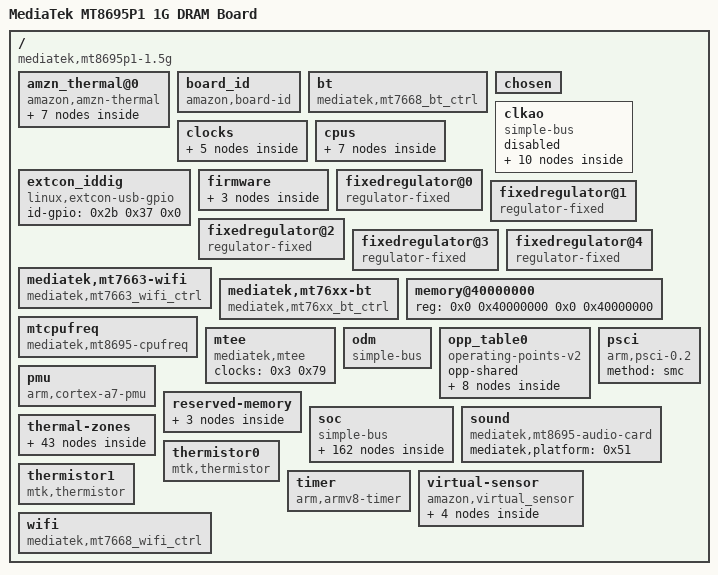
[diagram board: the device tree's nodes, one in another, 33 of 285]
/dts-v1/;

/ {
	#address-cells = <0x2>;
	#size-cells = <0x2>;
	compatible = "mediatek,mt8695p1-1.5g", "mediatek,mt8695";
	interrupt-parent = <0x1>;
	model = "MediaTek MT8695P1 1G DRAM Board";

	amzn_thermal@0 {
		compatible = "amazon,amzn-thermal";

		cooling_devices {

			cpucore_cool_cluster0 {
				cluster_id = <0x0>;
				device_type = "cpucore";
				dyn_coeff = <0x0>;
				min_state = <0x1>;
				node_name = "cpu_core_cluster0";
			};

			cpufreq_cool_cluster0 {
				cluster_id = <0x0>;
				device_type = "cpufreq";
				dyn_coeff = <0x8c>;
				min_state = <0xf4240>;
				node_name = "cpus";
			};

			gpufreq_cool {
				cluster_id = <0x0>;
				device_type = "gpufreq";
				dyn_coeff = <0x1b5>;
				min_state = <0x190>;
				node_name = "gpu";
			};

			wifi_cool_device {
				device_type = "wifi";
				min_state = <0x0>;
				node_name = "wifi_cool";
			};
		};

		cpu_core_cluster0 {
			#cooling-cells = <0x2>;
			linux,phandle = <0x49>;
			phandle = <0x49>;
		};

		wifi_cool {
			#cooling-cells = <0x2>;
			linux,phandle = <0x4b>;
			phandle = <0x4b>;
		};
	};

	board_id {
		compatible = "amazon,board-id";
		id0-gpio = <0x2b 0x4e 0x0>;
		id1-gpio = <0x2b 0x4f 0x0>;
		id2-gpio = <0x2b 0x50 0x0>;
	};

	bt {
		compatible = "mediatek,mt7668_bt_ctrl";
		interrupt-parent = <0x2b>;
		interrupts = <0x22 0x8>;
		pinctrl-0 = <0x40>;
		pinctrl-names = "default";
		status = "okay";
	};

	chosen {
		bootargs = "console=tty0 console=ttyS1,921600n1 earlycon=uart8250,mmio32,0x11003000 root=/dev/ram initrd=0x44000000,0x600000 loglevel=8 initcall_debug=1 androidboot.selinux=permissive androidboot.hardware=mt8695 androidboot.serialno=0123456789ABCDEF";
	};

	clkao {
		compatible = "simple-bus";
		status = "disabled";

		bring-up {
			clock-names = "0", "1", "2", "3", "4", "5", "6", "7", "8", "9", "10", "11", "12", "13", "14", "15", "16", "17", "18", "19", "20", "21", "22", "23", "24", "25", "26", "27", "28", "29", "30", "31", "32", "33", "34", "35", "36", "37", "38", "39", "40", "41", "42", "43", "44", "45", "46", "47", "48", "49", "50", "51", "52", "53", "54", "55", "56", "57", "58", "59", "60", "61", "62", "63", "64", "65", "66", "67", "68", "69", "70", "71", "72", "73", "74", "75", "76", "77", "78", "79", "80", "81", "82", "83", "84", "85", "86", "87", "88", "89", "90", "91", "92", "93", "94", "95", "96", "97", "98", "99", "100", "101", "102", "103", "104", "105", "106", "107", "108", "109", "110", "111", "112", "113", "114", "115", "116", "117", "118", "119", "120", "121", "122", "123", "124", "125", "126", "127", "128", "129", "130", "131", "132", "133", "134", "135", "136", "137", "138", "139", "140", "141", "142", "143", "144", "145", "146";
			clocks = <0x4 0x0 0x4 0x1 0x4 0x2 0x4 0x3 0x4 0x4 0x4 0x5 0x4 0x6 0x4 0x7 0x4 0x8 0x4 0x9 0x4 0xa 0x3 0x47 0x3 0x49 0x3 0x50 0x3 0x57 0x3 0x59 0x3 0x5d 0x3 0x5f 0x3 0x63 0x3 0x65 0x3 0x66 0x3 0x67 0x3 0x68 0x3 0x69 0x3 0x6a 0x3 0x6b 0x3 0x6c 0x3 0x6d 0x3 0x6e 0x3 0x6f 0x3 0x74 0x3 0x75 0x3 0x79 0x3 0x7a 0x3 0x7f 0x3 0x80 0x3 0x81 0x3 0x82 0x3 0x83 0x3 0x84 0x3 0x85 0x3 0x86 0x3 0x87 0x3 0x88 0xa 0x0 0xa 0x1 0xa 0x2 0xa 0x3 0xa 0x4 0x18 0x3 0x18 0x4 0x18 0x5 0x18 0x6 0x18 0x7 0x18 0x8 0x18 0x9 0x18 0xa 0x18 0xb 0x18 0xc 0x18 0xd 0x18 0xe 0x18 0xf 0x18 0x10 0x18 0x11 0x18 0x12 0x18 0x13 0x18 0x14 0x18 0x15 0x18 0x16 0x18 0x17 0x18 0x18 0x18 0x19 0x18 0x1a 0x18 0x1b 0x18 0x1c 0x18 0x1d 0x18 0x1e 0x18 0x1f 0x18 0x20 0x18 0x21 0x18 0x22 0x18 0x23 0x18 0x24 0x18 0x25 0x18 0x26 0x18 0x27 0x41 0x0 0x41 0x1 0x41 0x2 0x41 0x3 0x37 0x0 0x37 0x1 0x37 0x2 0x37 0x3 0x37 0x4 0x37 0x5 0x37 0x6 0x37 0x7 0x37 0x8 0x37 0x9 0x37 0xa 0x37 0xb 0x37 0xc 0x37 0xd 0x37 0xe 0x37 0xf 0x37 0x10 0x37 0x11 0x37 0x12 0x37 0x13 0x37 0x14 0x37 0x15 0x37 0x16 0x37 0x17 0x37 0x18 0x37 0x19 0x37 0x1a 0x37 0x1b 0x37 0x1c 0x37 0x1d 0x37 0x1e 0x38 0x0 0x38 0x1 0x38 0x2 0x38 0x3 0x38 0x4 0x38 0x5 0x38 0x6 0x38 0x7 0x38 0x8 0x38 0x9 0x38 0xa 0x38 0xb 0x38 0xc 0x38 0xd 0x38 0xe 0x38 0xf 0x38 0x10 0x3d 0x0 0x3d 0x1 0x3e 0x0 0x3e 0x1 0x3f 0x0 0x3f 0x1 0x42 0x0 0x42 0x1>;
			compatible = "mediatek,clk-bring-up";
		};

		bring-up-pd-dis_c {
			compatible = "mediatek,scpsys-bring-up";
			power-domains = <0x17 0x4>;
		};

		bring-up-pd-dis_m {
			compatible = "mediatek,scpsys-bring-up";
			power-domains = <0x17 0x2>;
		};

		bring-up-pd-dis_s {
			compatible = "mediatek,scpsys-bring-up";
			power-domains = <0x17 0x3>;
		};

		bring-up-pd-dolby {
			compatible = "mediatek,scpsys-bring-up";
			power-domains = <0x17 0x5>;
		};

		bring-up-pd-eth {
			compatible = "mediatek,scpsys-bring-up";
			power-domains = <0x17 0x7>;
		};

		bring-up-pd-mm {
			compatible = "mediatek,scpsys-bring-up";
			power-domains = <0x17 0x0>;
		};

		bring-up-pd-usb {
			compatible = "mediatek,scpsys-bring-up";
			power-domains = <0x17 0x8>;
		};

		bring-up-pd-vdec {
			compatible = "mediatek,scpsys-bring-up";
			power-domains = <0x17 0x1>;
		};

		bring-up-pd-venc {
			compatible = "mediatek,scpsys-bring-up";
			power-domains = <0x17 0x6>;
		};
	};

	clocks {

		clk12m {
			#clock-cells = <0x0>;
			clock-frequency = <0xb71b00>;
			compatible = "fixed-clock";
		};

		clk13m {
			#clock-cells = <0x0>;
			clock-frequency = <0xc65d40>;
			compatible = "fixed-clock";
			linux,phandle = <0xb>;
			phandle = <0xb>;
		};

		clk26m {
			#clock-cells = <0x0>;
			clock-frequency = <0x18cba80>;
			clock-output-names = "clk26m";
			compatible = "fixed-clock";
			linux,phandle = <0x21>;
			phandle = <0x21>;
		};

		clk6m {
			#clock-cells = <0x0>;
			clock-frequency = <0x5b8d80>;
			compatible = "fixed-clock";
		};

		clk_null {
			#clock-cells = <0x0>;
			clock-frequency = <0x0>;
			compatible = "fixed-clock";
		};
	};

	cpus {
		#address-cells = <0x1>;
		#cooling-cells = <0x2>;
		#size-cells = <0x0>;
		linux,phandle = <0x46>;
		phandle = <0x46>;

		cpu@0 {
			clock-frequency = <0x6553f100>;
			clock-names = "cpu", "intermediate", "armpll";
			clocks = <0x2 0x0 0x3 0x20 0x4 0x0>;
			compatible = "arm,cortex-a53";
			cpu-release-addr = <0x0 0x40000200>;
			device_type = "cpu";
			enable-method = "psci";
			operating-points-v2 = <0x5>;
			proc-supply = <0x8>;
			reg = <0x0>;
			sched-energy-costs = <0x6 0x7>;
		};

		cpu@1 {
			clock-frequency = <0x6553f100>;
			clock-names = "cpu", "intermediate", "armpll";
			clocks = <0x2 0x0 0x3 0x20 0x4 0x0>;
			compatible = "arm,cortex-a53";
			cpu-release-addr = <0x0 0x40000200>;
			device_type = "cpu";
			enable-method = "psci";
			operating-points-v2 = <0x5>;
			proc-supply = <0x8>;
			reg = <0x1>;
			sched-energy-costs = <0x6 0x7>;
		};

		cpu@2 {
			clock-frequency = <0x6553f100>;
			clock-names = "cpu", "intermediate", "armpll";
			clocks = <0x2 0x0 0x3 0x20 0x4 0x0>;
			compatible = "arm,cortex-a53";
			cpu-release-addr = <0x0 0x40000200>;
			device_type = "cpu";
			enable-method = "psci";
			operating-points-v2 = <0x5>;
			proc-supply = <0x8>;
			reg = <0x2>;
			sched-energy-costs = <0x6 0x7>;
		};

		cpu@3 {
			clock-frequency = <0x6553f100>;
			clock-names = "cpu", "intermediate", "armpll";
			clocks = <0x2 0x0 0x3 0x20 0x4 0x0>;
			compatible = "arm,cortex-a53";
			cpu-release-addr = <0x0 0x40000200>;
			device_type = "cpu";
			enable-method = "psci";
			operating-points-v2 = <0x5>;
			proc-supply = <0x8>;
			reg = <0x3>;
			sched-energy-costs = <0x6 0x7>;
		};

		energy-costs {

			mt8695-cluster-cost0 {
				busy-cost-data = <0x400 0x0>;
				idle-cost-data = <0x0 0x0>;
				linux,phandle = <0x7>;
				phandle = <0x7>;
			};

			mt8695-core-cost0 {
				busy-cost-data = <0x400 0x0>;
				idle-cost-data = <0x0 0x0>;
				linux,phandle = <0x6>;
				phandle = <0x6>;
			};
		};
	};

	extcon_iddig {
		compatible = "linux,extcon-usb-gpio";
		id-gpio = <0x2b 0x37 0x0>;
		linux,phandle = <0x31>;
		phandle = <0x31>;
	};

	firmware {

		android {
			compatible = "android,firmware";

			fstab {
				compatible = "android,fstab";

				vendor {
					compatible = "android,vendor";
					dev = "/dev/block/platform/soc/11230000.mmc/by-name/vendor";
					fsmgr_flags = "wait,verify";
					mnt_flags = "ro";
					type = "ext4";
				};
			};
		};
	};

	fixedregulator@0 {
		compatible = "regulator-fixed";
		enable-active-high;
		linux,phandle = <0x25>;
		phandle = <0x25>;
		regulator-always-on;
		regulator-max-microvolt = <0x325aa0>;
		regulator-min-microvolt = <0x325aa0>;
		regulator-name = "mmc_power";
	};

	fixedregulator@1 {
		compatible = "regulator-fixed";
		enable-active-high;
		linux,phandle = <0x26>;
		phandle = <0x26>;
		regulator-always-on;
		regulator-max-microvolt = <0x1b7740>;
		regulator-min-microvolt = <0x1b7740>;
		regulator-name = "mmc_io";
	};

	fixedregulator@2 {
		compatible = "regulator-fixed";
		enable-active-high;
		linux,phandle = <0x30>;
		phandle = <0x30>;
		regulator-always-on;
		regulator-max-microvolt = <0x4c4b40>;
		regulator-min-microvolt = <0x4c4b40>;
		regulator-name = "vbus";
		regulator-type = "voltage";
	};

	fixedregulator@3 {
		compatible = "regulator-fixed";
		enable-active-high;
		linux,phandle = <0x2c>;
		phandle = <0x2c>;
		regulator-always-on;
		regulator-max-microvolt = <0x325aa0>;
		regulator-min-microvolt = <0x325aa0>;
		regulator-name = "sdio_power";
	};

	fixedregulator@4 {
		compatible = "regulator-fixed";
		enable-active-high;
		gpio = <0x2b 0x7e 0x0>;
		linux,phandle = <0x2d>;
		phandle = <0x2d>;
		regulator-max-microvolt = <0x1b7740>;
		regulator-min-microvolt = <0x1b7740>;
		regulator-name = "sdio_io";
	};

	mediatek,mt7663-wifi {
		compatible = "mediatek,mt7663_wifi_ctrl";
		interrupt-parent = <0x2b>;
		interrupts = <0x21 0x2>;
		status = "okay";
	};

	mediatek,mt76xx-bt {
		compatible = "mediatek,mt76xx_bt_ctrl";
		interrupt-parent = <0x2b>;
		interrupts = <0x22 0x2>;
		status = "okay";
	};

	memory@40000000 {
		device_type = "memory";
		reg = <0x0 0x40000000 0x0 0x40000000>;
	};

	mtcpufreq {
		compatible = "mediatek,mt8695-cpufreq";
	};

	mtee {
		clock-names = "GCPU";
		clocks = <0x3 0x79>;
		compatible = "mediatek,mtee";
	};

	odm {
		compatible = "simple-bus";
	};

	opp_table0 {
		compatible = "operating-points-v2";
		linux,phandle = <0x5>;
		opp-shared;
		phandle = <0x5>;

		opp00 {
			opp-hz = <0x0 0x2cf12080>;
			opp-microvolt = <0xc3500>;
		};

		opp01 {
			opp-hz = <0x0 0x3c706980>;
			opp-microvolt = <0xc3500>;
		};

		opp02 {
			opp-hz = <0x0 0x44300e00>;
			opp-microvolt = <0xd10ba>;
		};

		opp03 {
			opp-hz = <0x0 0x4a62f800>;
			opp-microvolt = <0xdbba0>;
		};

		opp04 {
			opp-hz = <0x0 0x5095e200>;
			opp-microvolt = <0xe7ef0>;
		};

		opp05 {
			opp-hz = <0x0 0x56c8cc00>;
			opp-microvolt = <0xf29d6>;
		};

		opp06 {
			opp-hz = <0x0 0x5f4ecdc0>;
			opp-microvolt = <0x101dfa>;
		};

		opp07 {
			opp-hz = <0x0 0x64bb5a80>;
			opp-microvolt = <0x10c8e0>;
		};
	};

	pmu {
		compatible = "arm,cortex-a7-pmu";
		interrupt-parent = <0x9>;
		interrupts = <0x1 0x7 0x8>;
	};

	psci {
		compatible = "arm,psci-0.2";
		method = "smc";
	};

	reserved-memory {
		#address-cells = <0x2>;
		#size-cells = <0x2>;
		ranges;

		atf-reserved-memory@43000000 {
			compatible = "mediatek,mt8695-atf-reserved-memory";
			no-map;
			reg = <0x0 0x43000000 0x0 0x30000>;
		};

		minirdump-reserved-memory@444f0000 {
			compatible = "mediatek,minirdump";
			reg = <0x0 0x444f0000 0x0 0x10000>;
		};

		ram_console-reserved-memory@44400000 {
			compatible = "mediatek,ram_console";
			reg = <0x0 0x44400000 0x0 0x10000>;
		};
	};

	soc {
		#address-cells = <0x2>;
		#size-cells = <0x2>;
		compatible = "simple-bus";
		ranges;

		adc@11001000 {
			#io-channel-cells = <0x1>;
			clock-names = "main";
			clocks = <0x18 0x1b>;
			compatible = "mediatek,mt8695-auxadc", "mediatek,mt2701-auxadc";
			linux,phandle = <0x1e>;
			phandle = <0x1e>;
			reg = <0x0 0x11001000 0x0 0x1000>;
		};

		apxgpt@10008000 {
			clock-names = "clk13m", "clk13m";
			clocks = <0xb 0xb>;
			compatible = "mediatek,mt6577-timer";
			interrupts = <0x0 0x98 0x8>;
			reg = <0x0 0x10008000 0x0 0x1000>;
		};

		audio-controller@11220000 {
			clock-names = "apll1", "apll2", "sys_26m", "apll1_ck", "apll1_d2", "apll1_d4", "apll1_d8", "apll1_d16", "apll2_ck", "apll2_d2", "apll2_d4", "apll2_d8", "apll2_d16", "univpll2_d4", "univpll2_d2", "syspll_d5", "univpll_d3", "syspll_d2", "tvdpll_ck", "univpll_d2", "syspll1_d4", "syspll2_d4", "univpll3_d2", "univpll2_d8", "syspll3_d2", "syspll3_d4", "i2si1_sel", "apll_div5", "apll_div_pdn5", "i2si2_sel", "apll_div6", "apll_div_pdn6", "i2so1_sel", "apll_div0", "apll_div_pdn0", "i2so2_sel", "tdmin_sel", "apll_div1", "apll_div_pdn1", "apll_sel", "apll2_sel", "a1sys_hp_sel", "a2sys_hp_sel", "asm_l_sel", "asm_m_sel", "asm_h_sel", "intdir_sel", "aud_intbus_sel";
			clocks = <0x4 0x9 0x4 0xa 0x3 0x34 0x3 0x22 0x3 0x23 0x3 0x24 0x3 0x25 0x3 0x26 0x3 0x27 0x3 0x28 0x3 0x29 0x3 0x2a 0x3 0x2b 0x3 0x1a 0x3 0x19 0x3 0xa 0x3 0x18 0x3 0x3 0x3 0x38 0x3 0x14 0x3 0x5 0x3 0x9 0x3 0x1d 0x3 0x1b 0x3 0xb 0x3 0xc 0x3 0x72 0x3 0x81 0x3 0x85 0x3 0x73 0x3 0x82 0x3 0x86 0x3 0x70 0x3 0x7f 0x3 0x83 0x3 0x71 0x3 0x7e 0x3 0x80 0x3 0x84 0x3 0x69 0x3 0x6a 0x3 0x6b 0x3 0x6c 0x3 0x6d 0x3 0x6e 0x3 0x6f 0x3 0x57 0x3 0x59>;
			compatible = "mediatek,mt8695-afe-pcm";
			interrupts = <0x0 0xf2 0x8 0x0 0x8e 0x8>;
			linux,phandle = <0x51>;
			mediatek,dmic-wire-mode = <0x0>;
			phandle = <0x51>;
			reg = <0x0 0x11220000 0x0 0x2000>;
		};

		codec@16000000 {
			clock-names = "vdecsel", "vdecslowsel", "laesel", "vdecpll", "osdpll_d2";
			clocks = <0x3 0x48 0x3 0x49 0x3 0x47 0x3 0x37 0x3 0x2d>;
			compatible = "mediatek,mt8695-vcodec-dec";
			interrupts = <0x0 0xd4 0x8 0x0 0xd3 0x8>;
			larbs = <0xf 0x14>;
			power-domains = <0x17 0x1>;
			reg = <0x0 0x16000000 0x0 0x40000>;
		};

		codec@18004000 {
			clock-names = "venc_sel", "venc_pll";
			clocks = <0x3 0x4a 0x3 0x15>;
			compatible = "mediatek,mt8695-venc";
			interrupts = <0x0 0xc7 0x8>;
			larbs = <0x10>;
			power-domains = <0x17 0x6>;
			reg = <0x0 0x18000000 0x0 0x1000 0x0 0x18004000 0x0 0x1000>;
		};

		disp_dovi_core@14009000 {
			compatible = "mediatek,mt8695-dovi_core";
			reg = <0x0 0x14009000 0x0 0x500 0x0 0x1400a000 0x0 0x500 0x0 0x1400b000 0x0 0x500>;
		};

		disp_fmt@14001000 {
			compatible = "mediatek,mt8695-fmt";
			interrupts = <0x0 0xb9 0x8 0x0 0xba 0x8>;
			reg = <0x0 0x10000000 0x0 0x1000 0x0 0x14001000 0x0 0x400 0x0 0x15000000 0x0 0x100 0x0 0x15001000 0x0 0x100 0x0 0x15008000 0x0 0x100>;
		};

		disp_hdr_ctrl@14000000 {
			compatible = "mediatek,mt8695-hdr-ctrl";
			reg = <0x0 0x14000000 0x0 0x100 0x0 0x15000000 0x0 0x100>;
		};

		disp_hdr_main@15002000 {
			compatible = "mediatek,mt8695-hdr-main";
			reg = <0x0 0x15002000 0x0 0x1000>;
		};

		disp_hdr_osd@14002000 {
			compatible = "mediatek,mt8695-hdr-osd";
			reg = <0x0 0x14002000 0x0 0x1000>;
		};

		disp_hdr_sub@15009000 {
			compatible = "mediatek,mt8695-hdr-sub";
			reg = <0x0 0x15009000 0x0 0x1000>;
		};

		disp_osd@14004300 {
			compatible = "mediatek,mt8695-osd";
			interrupts = <0x0 0xbe 0x8>;
			reg = <0x0 0x14004300 0x0 0x300 0x0 0x14003000 0x0 0x300 0x0 0x14001c00 0x0 0x100 0x0 0x1400c380 0x0 0x10>;
		};

		disp_p2i@14001700 {
			compatible = "mediatek,mt8695-p2i";
			reg = <0x0 0x14001700 0x0 0x100>;
		};

		disp_vdo@15001000 {
			compatible = "mediatek,mt8695-vdo";
			interrupts = <0x0 0x59 0x4>;
			reg = <0x0 0x15001000 0x0 0x1000 0x0 0x15008000 0x0 0x1000>;
		};

		disp_vdout@14001500 {
			compatible = "mediatek,mt8695-vdout";
			reg = <0x0 0x14001500 0x0 0x100 0x0 0x14001c00 0x0 0x100>;
		};

		disp_videoin@14001b00 {
			compatible = "mediatek,mt8695-videoin";
			reg = <0x0 0x14001b00 0x0 0x100 0x0 0x1400e300 0x0 0x100>;
		};

		display-pm-disp-m {
			clock-names = "vdo3", "dispfmt3", "mvdo_hdr2sdr", "mvdo_bt2020";
			clocks = <0x38 0x0 0x38 0x1 0x38 0x2 0x38 0x3>;
			compatible = "mediatek,mt8695-disp-clk";
			mediatek,pm_type = <0x2>;
			power-domains = <0x17 0x2>;
		};

		display-pm-disp-s {
			clock-names = "vdo4", "dispfmt4", "svdo_hdr2sdr", "svdo_bt2020";
			clocks = <0x38 0x7 0x38 0x8 0x38 0x9 0x38 0xa>;
			compatible = "mediatek,mt8695-disp-clk";
			mediatek,pm_type = <0x3>;
			power-domains = <0x17 0x3>;
		};

		display-pm-dolby {
			clock-names = "dolby1", "dolby2", "dolby3";
			clocks = <0x37 0x18 0x37 0x19 0x37 0x1a>;
			compatible = "mediatek,mt8695-disp-clk";
			mediatek,pm_type = <0x1>;
			power-domains = <0x17 0x5>;
		};

		display-pm-mm {
			clock-names = "tvdpll", "tvdpll_d2", "osdpll", "osdpll_d2", "osdpll_d4", "hd_sel", "sd_sel", "osd_sel", "vdo3_sel", "vdo4_sel", "clk26m", "vdout_sys", "fmt_tg", "osd_tve", "osd_fhd", "osd_uhd", "p2i", "scler", "sdppf", "vdoin", "sdr2hdr", "osd_premix", "dolby_mix", "vm";
			clocks = <0x3 0x38 0x3 0x39 0x3 0x2c 0x3 0x2d 0x3 0x2f 0x3 0x5d 0x3 0x45 0x3 0x5a 0x3 0x5b 0x3 0x5c 0x21 0x37 0xa 0x37 0xb 0x37 0xf 0x37 0x10 0x37 0x11 0x37 0x12 0x37 0x15 0x37 0x16 0x37 0x17 0x37 0x1b 0x37 0x1c 0x37 0x1d 0x37 0x1e>;
			compatible = "mediatek,mt8695-disp-clk";
			mediatek,pm_type = <0x0>;
			power-domains = <0x17 0x0>;
		};

		dma-controller@11000280 {
			#dma-cells = <0x1>;
			clock-names = "apdma";
			clocks = <0x18 0xf>;
			compatible = "mediatek,mt8695-uart-dma", "mediatek,mt6577-uart-dma";
			dma-33bits;
			interrupts = <0x0 0x65 0x8 0x0 0x66 0x8 0x0 0x67 0x8 0x0 0x68 0x8 0x0 0x69 0x8 0x0 0x6a 0x8>;
			linux,phandle = <0x19>;
			phandle = <0x19>;
			reg = <0x0 0x11000280 0x0 0x80 0x0 0x11000300 0x0 0x80 0x0 0x11000380 0x0 0x80 0x0 0x11000400 0x0 0x80 0x0 0x11000480 0x0 0x80 0x0 0x11000500 0x0 0x80>;
		};

		efuse@10206000 {
			#address-cells = <0x1>;
			#size-cells = <0x1>;
			compatible = "mediatek,mt8695-efuse", "mediatek,efuse";
			reg = <0x0 0x10206000 0x0 0x1000>;

			calib@180 {
				linux,phandle = <0x1f>;
				phandle = <0x1f>;
				reg = <0x180 0xc>;
			};

			calib@188 {
				linux,phandle = <0x39>;
				phandle = <0x39>;
				reg = <0x188 0x10>;
			};

			calib@18c {
				linux,phandle = <0x34>;
				phandle = <0x34>;
				reg = <0x18c 0x4>;
			};

			calib@190 {
				linux,phandle = <0x35>;
				phandle = <0x35>;
				reg = <0x190 0x4>;
			};

			calib@580 {
				linux,phandle = <0x20>;
				phandle = <0x20>;
				reg = <0x580 0x10>;
			};
		};

		emi@10203000 {
			compatible = "mediatek,mt8695-emi";
			reg = <0x0 0x10203000 0x0 0x1000 0x0 0x10105000 0x0 0x1000 0x0 0x1010d000 0x0 0x1000>;
		};

		emi_mpu@1020e000 {
			compatible = "mediatek,mt8695-emi_mpu";
			interrupts = <0x0 0x88 0x4>;
			reg = <0x0 0x1020e000 0x0 0x1000>;
		};

		eth@1101a000 {
			clock-names = "axi_dram", "apb_reg", "mac_ext";
			clocks = <0x18 0x20 0x18 0x21 0x3 0x74>;
			compatible = "mediatek,mt8695-ethernet";
			interrupts = <0x0 0xed 0x8>;
			power-domains = <0x17 0x7>;
			reg = <0x0 0x1101a000 0x0 0x380>;
			status = "disabled";
		};

		fhctl@10209e00 {
			compatible = "mediatek,mt8695-fhctl";
			reg = <0x0 0x10209e00 0x0 0x200>;
		};

		gpu@13000000 {
			#cooling-cells = <0x2>;
			clock-frequency = <0x17d78400>;
			compatible = "mediatek,mt8695-clark";
			interrupt-names = "RGX";
			interrupts = <0x0 0xe1 0x8>;
			linux,phandle = <0x4a>;
			phandle = <0x4a>;
			reg = <0x0 0x13000000 0x0 0x80000>;
		};

		hdmitx@14006000 {
			clock-names = "hdmi_hdclk", "hdmi_sdclk", "hdmi_hdcp", "hdmi_hdcp24", "hdmi_rgb2hdmien", "hdmi_hdmien", "hdmi_sdcksel", "hdmi_hdtvd", "hdmi_sdosd", "hdmi_cec";
			clocks = <0x3 0x5d 0x3 0x45 0x3 0x65 0x3 0x66 0x37 0x14 0x37 0x13 0x4 0xb 0x3 0x3b 0x3 0x31 0xa 0x4>;
			compatible = "mediatek,mt8695-hdmitx20";
			hdmi,filter_switch_gpio = <0x2b 0x51 0x0>;
			interrupts = <0x0 0xc3 0x4 0x0 0xaf 0x8>;
			nvmem-cell-names = "hdmi_calibration";
			nvmem-cells = <0x39>;
			pinctrl-0 = <0x3a>;
			pinctrl-1 = <0x3b>;
			pinctrl-2 = <0x3c>;
			pinctrl-names = "default", "5vhigh", "5vlow";
			power-domains = <0x17 0x0>;
			reg = <0x0 0x14001800 0x0 0x100 0x0 0x10002000 0x0 0x100 0x0 0x10002400 0x0 0x100 0x0 0x14006000 0x0 0x1000 0x0 0x11702000 0x0 0x100>;
			status = "okay";
		};

		i2c@11007000 {
			#address-cells = <0x1>;
			#size-cells = <0x0>;
			clock-div = <0x4>;
			clock-names = "main", "dma";
			clocks = <0x18 0x16 0x18 0xf>;
			compatible = "mediatek,mt8695-i2c", "mediatek,mt2712-i2c";
			interrupts = <0x0 0x54 0x8>;
			pinctrl-0 = <0x1b>;
			pinctrl-names = "default";
			reg = <0x0 0x11007000 0x0 0x90 0x0 0x11000080 0x0 0x80>;
			status = "okay";
		};

		i2c@11008000 {
			#address-cells = <0x1>;
			#size-cells = <0x0>;
			clock-div = <0x4>;
			clock-names = "main", "dma";
			clocks = <0x18 0x17 0x18 0xf>;
			compatible = "mediatek,mt8695-i2c", "mediatek,mt2712-i2c";
			interrupts = <0x0 0x55 0x8>;
			pinctrl-0 = <0x1c>;
			pinctrl-names = "default";
			reg = <0x0 0x11008000 0x0 0x90 0x0 0x11000100 0x0 0x80>;
			status = "okay";

			mt6393regulator@0x60 {
				compatible = "mediatek,mt6393-regulator";
				reg = <0x60>;

				buck_vddr {
					regulator-always-on;
					regulator-boot-on;
					regulator-max-microvolt = <0x10c8e0>;
					regulator-min-microvolt = <0x10c8e0>;
					regulator-name = "vddr";
				};

				buck_vio18 {
					regulator-always-on;
					regulator-boot-on;
					regulator-max-microvolt = <0x1b7740>;
					regulator-min-microvolt = <0x1b7740>;
					regulator-name = "vio18";
				};

				buck_vio33 {
					regulator-always-on;
					regulator-boot-on;
					regulator-max-microvolt = <0x325aa0>;
					regulator-min-microvolt = <0x325aa0>;
					regulator-name = "vio33";
				};

				buck_vproc {
					linux,phandle = <0x8>;
					phandle = <0x8>;
					regulator-always-on;
					regulator-boot-on;
					regulator-max-microvolt = <0x154456>;
					regulator-min-microvolt = <0x927c0>;
					regulator-name = "vproc";
				};

				ldo_sd {
					regulator-max-microvolt = <0x325aa0>;
					regulator-min-microvolt = <0x325aa0>;
					regulator-name = "sd";
				};
			};
		};

		i2c@11009000 {
			#address-cells = <0x1>;
			#size-cells = <0x0>;
			clock-div = <0x4>;
			clock-names = "main", "dma";
			clocks = <0x18 0x18 0x18 0xf>;
			compatible = "mediatek,mt8695-i2c", "mediatek,mt2712-i2c";
			interrupts = <0x0 0x56 0x8>;
			pinctrl-0 = <0x1d>;
			pinctrl-names = "default";
			reg = <0x0 0x11009000 0x0 0x90 0x0 0x11000180 0x0 0x80>;
			status = "okay";

			md1122-phy@60 {
				compatible = "mediatek,md1122";
				reg = <0x60>;
			};

			rt5738_buck@55 {
				compatible = "richtek,rt5738l";
				ramp_down = <0x3>;
				ramp_up = <0x1>;
				reg = <0x55>;
				regulator-always-on;
				regulator-boot-on;
				regulator-max-microvolt = <0x13d620>;
				regulator-min-microvolt = <0x493e0>;
				regulator-name = "rt5738-vsram";
				status = "disabled";
			};
		};

		i2c@11010000 {
			#address-cells = <0x1>;
			#size-cells = <0x0>;
			clock-div = <0x4>;
			clock-names = "main", "dma";
			clocks = <0x18 0x19 0x18 0xf>;
			compatible = "mediatek,mt8695-i2c", "mediatek,mt2712-i2c";
			interrupts = <0x0 0x57 0x8>;
			pinctrl-0 = <0x22>;
			pinctrl-names = "default";
			reg = <0x0 0x11010000 0x0 0x90 0x0 0x11000200 0x0 0x80>;
			status = "okay";
		};

		ice_debug {
			clock-names = "ice_dbg";
			clocks = <0xa 0x0>;
			compatible = "mediatek,mt8695-ice_debug", "mediatek,mt2701-ice_debug";
		};

		imgresz@1500c000 {
			clock-names = "imgrz_cg", "imgrz_sel", "syspll_d2", "mmpll", "univpll_d3", "osdpll_d2", "univpll_d5";
			clocks = <0x38 0xc 0x3 0x4c 0x3 0x3 0x3 0x35 0x3 0x18 0x3 0x2d 0x3 0x1c>;
			compatible = "mediatek,mt8695-imgresz";
			interrupts = <0x0 0x114 0x8>;
			iommus = <0x16 0xc6 0x16 0xc8 0x16 0xca>;
			mediatek,imgreszid = <0x0>;
			mediatek,larb = <0x13>;
			power-domains = <0x17 0x4>;
			reg = <0x0 0x1500c000 0x0 0x1000>;
		};

		imgresz@1500d000 {
			clock-names = "imgrz_cg", "imgrz_sel", "syspll_d2", "mmpll", "univpll_d3", "osdpll_d2", "univpll_d5";
			clocks = <0x38 0xc 0x3 0x4c 0x3 0x3 0x3 0x35 0x3 0x18 0x3 0x2d 0x3 0x1c>;
			compatible = "mediatek,mt8695-imgresz";
			interrupts = <0x0 0x113 0x8>;
			iommus = <0x16 0xc7 0x16 0xc9 0x16 0xcb>;
			mediatek,imgreszid = <0x1>;
			mediatek,larb = <0x13>;
			power-domains = <0x17 0x4>;
			reg = <0x0 0x1500d000 0x0 0x1000>;
		};

		interrupt-controller@0c000000 {
			#interrupt-cells = <0x3>;
			#redistributor-regions = <0x1>;
			compatible = "arm,gic-v3";
			interrupt-controller;
			interrupt-parent = <0x9>;
			interrupts = <0x1 0x9 0xf04>;
			linux,phandle = <0x9>;
			phandle = <0x9>;
			reg = <0x0 0xc000000 0x0 0x40000 0x0 0xc100000 0x0 0x200000>;
		};

		intpol-controller@10220a80 {
			#interrupt-cells = <0x3>;
			compatible = "mediatek,mt8173-sysirq", "mediatek,mt6577-sysirq";
			interrupt-controller;
			interrupt-parent = <0x9>;
			linux,phandle = <0x1>;
			phandle = <0x1>;
			reg = <0x0 0x10220a80 0x0 0x28>;
		};

		iommu@10205000 {
			#iommu-cells = <0x1>;
			clock-names = "bclk";
			clocks = <0xa 0x2>;
			compatible = "mediatek,mt8695-m4u";
			interrupts = <0x0 0x93 0x8>;
			linux,phandle = <0x16>;
			mediatek,larbs = <0xe 0xf 0x10 0x11 0x12 0x13 0x14 0x15>;
			phandle = <0x16>;
			reg = <0x0 0x10205000 0x0 0x1000>;
		};

		irrx@1000d000 {
			clock-names = "irrx_clock";
			clocks = <0x3 0x67>;
			compatible = "mediatek,mt8695-irrx";
			interrupts = <0x0 0xa1 0x8>;
			pinctrl-0 = <0xd>;
			pinctrl-names = "default";
			reg = <0x0 0x1000d000 0x0 0x1000>;
			status = "okay";
		};

		irt_dma@1500b000 {
			clock-names = "irt_dma";
			clocks = <0x38 0xb>;
			compatible = "mediatek,mt8695-irt";
			interrupts = <0x0 0x115 0x8>;
			iommus = <0x16 0xcc>;
			mediatek,larb = <0x13>;
			power-domains = <0x17 0x4>;
			reg = <0x0 0x1500b000 0x0 0x100 0x0 0x15000000 0x0 0x100>;
		};

		larb@14000000 {
			clock-names = "apb", "smi";
			clocks = <0x37 0x2 0x38 0x6>;
			compatible = "mediatek,mt8695-smi-larb";
			linux,phandle = <0x15>;
			mediatek,larbidx = <0x8>;
			mediatek,smi = <0x36>;
			phandle = <0x15>;
			power-domains = <0x17 0x2>;
			reg = <0x0 0x14000000 0x0 0x1000>;
		};

		larb@1400c000 {
			clock-names = "apb", "smi";
			clocks = <0x37 0x1 0x37 0x1>;
			compatible = "mediatek,mt8695-smi-larb";
			linux,phandle = <0xe>;
			mediatek,larbidx = <0x0>;
			mediatek,smi = <0x36>;
			phandle = <0xe>;
			power-domains = <0x17 0x0>;
			reg = <0x0 0x1400c000 0x0 0x1000>;
		};

		larb@1400e000 {
			clock-names = "apb", "smi";
			clocks = <0x37 0x4 0x37 0x4>;
			compatible = "mediatek,mt8695-smi-larb";
			linux,phandle = <0x11>;
			mediatek,larbidx = <0x4>;
			mediatek,smi = <0x36>;
			phandle = <0x11>;
			power-domains = <0x17 0x0>;
			reg = <0x0 0x1400e000 0x0 0x1000>;
		};

		larb@15004000 {
			clock-names = "apb", "smi";
			clocks = <0x37 0x6 0x38 0x4>;
			compatible = "mediatek,mt8695-smi-larb";
			linux,phandle = <0x12>;
			mediatek,larbidx = <0x5>;
			mediatek,smi = <0x36>;
			phandle = <0x12>;
			power-domains = <0x17 0x2>;
			reg = <0x0 0x15004000 0x0 0x1000>;
		};

		larb@15005000 {
			clock-names = "apb", "smi";
			clocks = <0x37 0x7 0x38 0x5>;
			compatible = "mediatek,mt8695-smi-larb";
			linux,phandle = <0x13>;
			mediatek,larbidx = <0x6>;
			mediatek,smi = <0x36>;
			phandle = <0x13>;
			power-domains = <0x17 0x2>;
			reg = <0x0 0x15005000 0x0 0x1000>;
		};

		larb@1600e000 {
			clock-names = "apb", "smi", "asif";
			clocks = <0x37 0x8 0x3d 0x1 0x3d 0x0>;
			compatible = "mediatek,mt8695-smi-larb";
			linux,phandle = <0x14>;
			mediatek,larbidx = <0x7>;
			mediatek,smi = <0x36>;
			phandle = <0x14>;
			power-domains = <0x17 0x1>;
			reg = <0x0 0x1600e000 0x0 0x1000>;
		};

		larb@1602e000 {
			clock-names = "apb", "smi", "asif";
			clocks = <0x37 0x5 0x3e 0x1 0x3e 0x0>;
			compatible = "mediatek,mt8695-smi-larb";
			linux,phandle = <0xf>;
			mediatek,larbidx = <0x1>;
			mediatek,smi = <0x36>;
			phandle = <0xf>;
			power-domains = <0x17 0x1>;
			reg = <0x0 0x1602e000 0x0 0x1000>;
		};

		larb@18001000 {
			clock-names = "apb", "smi";
			clocks = <0x3f 0x0 0x3f 0x0>;
			compatible = "mediatek,mt8695-smi-larb";
			linux,phandle = <0x10>;
			mediatek,larbidx = <0x3>;
			mediatek,smi = <0x36>;
			phandle = <0x10>;
			power-domains = <0x17 0x6>;
			reg = <0x0 0x18001000 0x0 0x1000>;
		};

		mfg@13ffe000 {
			clock-names = "mfg_sel", "mfg_axi_in_sel", "mfg_slow_in_sel", "pll", "axi", "slow";
			clocks = <0x3 0x4b 0x3 0x64 0x3 0x63 0x3 0x35 0x3 0x43 0x3 0x1a>;
			compatible = "mediatek,mt8695-mfg";
			infracfg = <0xa>;
			reg = <0x0 0x13ffe000 0x0 0x1000 0x0 0x10006000 0x0 0x1000>;
		};

		mmc@11230000 {
			assigned-clock-parents = <0x3 0x3c>;
			assigned-clocks = <0x3 0x52>;
			bus-width = <0x8>;
			cap-mmc-highspeed;
			cap-mmc-hw-reset;
			clock-names = "source", "hclk", "source_cg";
			clocks = <0x18 0x10 0x18 0x26 0x18 0x23>;
			compatible = "mediatek,mt8695-mmc";
			hs400-ds-delay = <0x14019>;
			interrupts = <0x0 0x4f 0x8>;
			max-frequency = <0xbebc200>;
			mmc-hs200-1_8v;
			mmc-hs400-1_8v;
			non-removable;
			pinctrl-0 = <0x23>;
			pinctrl-1 = <0x24>;
			pinctrl-names = "default", "state_uhs";
			r_smpl = <0x0>;
			reg = <0x0 0x11230000 0x0 0x1000>;
			status = "okay";
			vmmc-supply = <0x25>;
			vqmmc-supply = <0x26>;
		};

		mmc@11240000 {
			clock-names = "source", "hclk", "source_cg";
			clocks = <0x18 0x11 0x3 0x43 0x18 0x24>;
			compatible = "mediatek,mt8695-mmc";
			interrupts = <0x0 0x50 0x8>;
			reg = <0x0 0x11240000 0x0 0x1000>;
			status = "disabled";
		};

		mtk_stc@11221750 {
			compatible = "mediatek,mt8695-stc";
			reg = <0x0 0x11221750 0x0 0x40>;
		};

		mtkfb {
			compatible = "mediatek,mtkfb";
			iommus = <0x16 0x80 0x16 0x0 0x16 0x81 0x16 0x82>;
			mediatek,larb = <0xe 0x11 0x12 0x13>;
			power-domains = <0x17 0x0>;
		};

		nfi@1100e000 {
			clock-names = "nfi_clk", "pad_clk";
			clocks = <0x21 0x21>;
			compatible = "mediatek,mt8695-nfc";
			interrupts = <0x0 0x60 0x8>;
			reg = <0x0 0x1100e000 0x0 0x1000>;
			status = "disabled";
		};

		nfiecc@1100f000 {
			clock-names = "nfiecc_clk";
			clocks = <0x21>;
			compatible = "mediatek,mt8695-ecc";
			interrupts = <0x0 0x5f 0x8>;
			reg = <0x0 0x1100f000 0x0 0x1000>;
			status = "disabled";
		};

		pinctrl@1000b000 {
			#gpio-cells = <0x2>;
			#interrupt-cells = <0x2>;
			compatible = "mediatek,mt8695-pinctrl";
			gpio-controller;
			interrupt-controller;
			interrupts = <0x0 0x99 0x4>;
			linux,phandle = <0x2b>;
			mediatek,pctl-regmap = <0xc>;
			phandle = <0x2b>;
			pins-are-numbered;
			reg = <0x0 0x1000b000 0x0 0x1000>;

			bt {
				linux,phandle = <0x40>;
				phandle = <0x40>;

				pins_cmd_dat {
					input-enable;
					pinmux = <0x1b00>;
				};
			};

			dat1_eint {
				linux,phandle = <0x2a>;
				phandle = <0x2a>;

				pins_dat1_eint {
					bias-pull-up = <0x66>;
					input-enable;
					pinmux = <0x2000>;
				};
			};

			hdmi {
				linux,phandle = <0x3a>;
				phandle = <0x3a>;

				hdmi_cec {
					pinmux = <0x4801>;
				};

				hdmi_filter {
					output-high;
					pinmux = <0x5100>;
				};

				hdmi_hotplug {
					bias-pull-down;
					pinmux = <0x4901>;
				};

				hdmi_pins {
					bias-pull-up = <0x65>;
					drive-strength = <0xa>;
					pinmux = <0x4a01 0x4b01>;
				};
			};

			hdmi1 {
				linux,phandle = <0x3b>;
				phandle = <0x3b>;

				hdmi_5vh {
					output-high;
					pinmux = <0x3c00>;
				};
			};

			hdmi2 {
				linux,phandle = <0x3c>;
				phandle = <0x3c>;

				hdmi_5vl {
					output-low;
					pinmux = <0x3c00>;
				};
			};

			i2c0 {
				linux,phandle = <0x1b>;
				phandle = <0x1b>;

				pins_bus {
					bias-disable;
					pinmux = <0x7501 0x7601>;
				};
			};

			i2c1 {
				linux,phandle = <0x1c>;
				phandle = <0x1c>;

				pins_bus {
					bias-pull-up = <0x67>;
					drive-strength = <0x65>;
					pinmux = <0x3803 0x3903>;
				};
			};

			i2c2 {
				linux,phandle = <0x1d>;
				phandle = <0x1d>;

				pins_bus {
					bias-pull-up = <0x67>;
					drive-strength = <0x65>;
					pinmux = <0x4c02 0x4d02>;
				};
			};

			i2c3 {
				linux,phandle = <0x22>;
				phandle = <0x22>;

				pins_bus {
					bias-disable;
					pinmux = <0x6705 0x6805>;
				};
			};

			irrx_pin_ir {
				linux,phandle = <0xd>;
				phandle = <0xd>;

				pins_cmd_dat {
					bias-disable;
					pinmux = <0x4106>;
				};
			};

			mmc0@0 {
				linux,phandle = <0x24>;
				phandle = <0x24>;

				pins_clk {
					bias-pull-down = <0x66>;
					drive-strength = <0x6>;
					pinmux = <0x2401>;
				};

				pins_cmd_dat {
					bias-pull-up = <0x65>;
					drive-strength = <0x6>;
					input-enable;
					pinmux = <0x2c01 0x2b01 0x2a01 0x2901 0x2801 0x2701 0x2601 0x2501 0x2d01>;
				};

				pins_ds {
					bias-pull-down = <0x66>;
					drive-strength = <0x6>;
					pinmux = <0x2301>;
				};

				pins_rst {
					bias-pull-up;
					pinmux = <0x2e01>;
				};
			};

			mmc0default {
				linux,phandle = <0x23>;
				phandle = <0x23>;

				pins_clk {
					bias-pull-down = <0x66>;
					drive-strength = <0x6>;
					pinmux = <0x2401>;
				};

				pins_cmd_dat {
					bias-pull-up = <0x65>;
					drive-strength = <0x6>;
					input-enable;
					pinmux = <0x2c01 0x2b01 0x2a01 0x2901 0x2801 0x2701 0x2601 0x2501 0x2d01>;
				};

				pins_rst {
					bias-pull-up;
					pinmux = <0x2e01>;
				};
			};

			mmc2@0 {
				linux,phandle = <0x28>;
				phandle = <0x28>;

				pins_clk {
					bias-pull-down = <0x66>;
					drive-strength = <0x6>;
					pinmux = <0x1c01>;
				};

				pins_cmd_dat {
					bias-pull-up = <0x66>;
					drive-strength = <0x6>;
					input-enable;
					pinmux = <0x2101 0x2001 0x1f01 0x1e01 0x2201>;
				};
			};

			mmc2_dat1 {
				linux,phandle = <0x29>;
				phandle = <0x29>;

				pins_dat1 {
					bias-pull-up = <0x66>;
					drive-strength = <0x6>;
					input-enable;
					pinmux = <0x2001>;
				};
			};

			mmc2default {
				linux,phandle = <0x27>;
				phandle = <0x27>;

				pins_clk {
					bias-pull-down = <0x66>;
					drive-strength = <0x6>;
					pinmux = <0x1c01>;
				};

				pins_cmd_dat {
					bias-pull-up = <0x66>;
					drive-strength = <0x6>;
					input-enable;
					pinmux = <0x2101 0x2001 0x1f01 0x1e01 0x2201>;
				};
			};

			uart1default {
				linux,phandle = <0x1a>;
				phandle = <0x1a>;

				pins_rx {
					bias-pull-up;
					input-enable;
					pinmux = <0x3a03>;
				};

				pins_tx {
					pinmux = <0x3b03>;
				};
			};

			usb_iddig_pull_down {
				linux,phandle = <0x33>;
				phandle = <0x33>;

				pins_iddig {
					bias-pull-down;
					pinmux = <0x1301>;
				};
			};

			usb_iddig_pull_up {
				linux,phandle = <0x32>;
				phandle = <0x32>;

				pins_iddig {
					bias-pull-up;
					pinmux = <0x1301>;
				};
			};

			wifi {
				linux,phandle = <0x43>;
				phandle = <0x43>;

				pins_cmd_dat {
					input-enable;
					pinmux = <0x1a00>;
				};
			};
		};

		pseudo-m4u {
			compatible = "mediatek,mt8695-pseudo-m4u";
			iommus = <0x16 0xa2>;
		};

		pseudo-m4u-larb0 {
			compatible = "mediatek,mt8695-pseudo-port-m4u";
			iommus = <0x16 0x0 0x16 0x1>;
			mediatek,larbid = <0x0>;
		};

		pseudo-m4u-larb1 {
			compatible = "mediatek,mt8695-pseudo-port-m4u";
			iommus = <0x16 0x20 0x16 0x21 0x16 0x22 0x16 0x23 0x16 0x24 0x16 0x25 0x16 0x26 0x16 0x27 0x16 0x28 0x16 0x29 0x16 0x2a>;
			mediatek,larbid = <0x1>;
		};

		pseudo-m4u-larb2 {
			compatible = "mediatek,mt8695-pseudo-port-m4u";
			mediatek,larbid = <0x2>;
		};

		pseudo-m4u-larb3 {
			compatible = "mediatek,mt8695-pseudo-port-m4u";
			iommus = <0x16 0x60 0x16 0x61 0x16 0x62 0x16 0x63 0x16 0x64 0x16 0x65 0x16 0x66 0x16 0x67 0x16 0x68 0x16 0x69 0x16 0x6a>;
			mediatek,larbid = <0x3>;
		};

		pseudo-m4u-larb4 {
			compatible = "mediatek,mt8695-pseudo-port-m4u";
			iommus = <0x16 0x80 0x16 0x81 0x16 0x82 0x16 0x83 0x16 0x84 0x16 0x85 0x16 0x86>;
			mediatek,larbid = <0x4>;
		};

		pseudo-m4u-larb5 {
			compatible = "mediatek,mt8695-pseudo-port-m4u";
			iommus = <0x16 0xa0 0x16 0xa1 0x16 0xa2 0x16 0xa3 0x16 0xa4 0x16 0xa5 0x16 0xa6 0x16 0xa7 0x16 0xa8 0x16 0xa9>;
			mediatek,larbid = <0x5>;
		};

		pseudo-m4u-larb6 {
			compatible = "mediatek,mt8695-pseudo-port-m4u";
			iommus = <0x16 0xc0 0x16 0xc1 0x16 0xc2 0x16 0xc3 0x16 0xc4 0x16 0xc5 0x16 0xc6 0x16 0xc7 0x16 0xc8 0x16 0xc9 0x16 0xca 0x16 0xcb 0x16 0xcc>;
			mediatek,larbid = <0x6>;
		};

		pseudo-m4u-larb7 {
			compatible = "mediatek,mt8695-pseudo-port-m4u";
			iommus = <0x16 0xe0 0x16 0xe1 0x16 0xe2 0x16 0xe3 0x16 0xe4 0x16 0xe5>;
			mediatek,larbid = <0x7>;
		};

		pseudo-m4u-larb8 {
			compatible = "mediatek,mt8695-pseudo-port-m4u";
			iommus = <0x16 0x100 0x16 0x101>;
			mediatek,larbid = <0x8>;
		};

		rng@1020f000 {
			clock-names = "rng";
			clocks = <0xa 0x5>;
			compatible = "mediatek,mt8695-rng", "mediatek,mt7623-rng";
			reg = <0x0 0x1020f000 0x0 0x100>;
		};

		sdio@11250000 {
			assigned-clock-parents = <0x3 0x3d>;
			assigned-clocks = <0x3 0x54>;
			bus-width = <0x4>;
			cap-sd-highspeed;
			cap-sdio-irq;
			clock-names = "source", "hclk", "source_cg";
			clocks = <0x18 0x12 0x18 0x27 0x18 0x25>;
			compatible = "mediatek,mt8695-sdio";
			eint-gpios = <0x2b 0x20 0x0>;
			enable-sdio-wakeup;
			interrupts = <0x0 0x51 0x8>;
			keep-power-in-suspend;
			max-frequency = <0xbebc200>;
			non-removable;
			pinctrl-0 = <0x27>;
			pinctrl-1 = <0x28>;
			pinctrl-2 = <0x29>;
			pinctrl-3 = <0x2a>;
			pinctrl-names = "default", "state_uhs", "state_dat1", "state_eint";
			reg = <0x0 0x11250000 0x0 0x1000>;
			sd-uhs-sdr104;
			sd-uhs-sdr50;
			status = "okay";
			vmmc-supply = <0x2c>;
			vqmmc-supply = <0x2d>;
		};

		serial@11002000 {
			clock-names = "baud", "bus";
			clocks = <0x18 0x0 0x18 0x13>;
			compatible = "mediatek,mt8695-uart", "mediatek,mt6577-uart";
			dma-names = "tx", "rx";
			dmas = <0x19 0x0 0x19 0x1>;
			interrupts = <0x0 0x5b 0x8>;
			reg = <0x0 0x11002000 0x0 0x1000>;
			status = "okay";
		};

		serial@11003000 {
			clock-names = "baud", "bus";
			clocks = <0x18 0x1 0x18 0x14>;
			compatible = "mediatek,mt8695-uart", "mediatek,mt6577-uart";
			interrupts = <0x0 0x5c 0x8>;
			pinctrl-0 = <0x1a>;
			pinctrl-names = "default";
			reg = <0x0 0x11003000 0x0 0x1000>;
			status = "okay";
		};

		serial@11004000 {
			clock-names = "baud", "bus";
			clocks = <0x18 0x2 0x18 0x15>;
			compatible = "mediatek,mt8695-uart", "mediatek,mt6577-uart";
			dma-names = "tx", "rx";
			dmas = <0x19 0x4 0x19 0x5>;
			interrupts = <0x0 0x5d 0x8>;
			reg = <0x0 0x11004000 0x0 0x1000>;
			status = "disabled";
		};

		smi@1400d000 {
			clock-names = "apb", "smi";
			clocks = <0x37 0x0 0x37 0x0>;
			compatible = "mediatek,mt8695-smi-common";
			linux,phandle = <0x36>;
			phandle = <0x36>;
			power-domains = <0x17 0x0>;
			reg = <0x0 0x1400d000 0x0 0x1000>;
		};

		spi@1100a000 {
			#address-cells = <0x1>;
			#size-cells = <0x0>;
			clock-names = "parent-clk", "sel-clk", "spi-clk";
			clocks = <0x3 0x19 0x3 0x4e 0x18 0x1c>;
			compatible = "mediatek,mt8695-spi";
			interrupts = <0x0 0x76 0x8>;
			reg = <0x0 0x1100a000 0x0 0x100>;
			status = "disabled";
		};

		spi@11015000 {
			#address-cells = <0x1>;
			#size-cells = <0x0>;
			clock-names = "parent-clk", "sel-clk", "spi-clk";
			clocks = <0x3 0x19 0x3 0x4e 0x18 0x1e>;
			compatible = "mediatek,mt8695-spi";
			interrupts = <0x0 0x11c 0x8>;
			reg = <0x0 0x11015000 0x0 0x100>;
			status = "disabled";
		};

		svs@1100b000 {
			clock-names = "main_clk", "count_clk";
			clocks = <0x18 0x4 0x18 0x22>;
			compatible = "mediatek,mt8695-svs";
			interrupts = <0x0 0x7d 0x8>;
			nvmem-cell-names = "svs_calibration";
			nvmem-cells = <0x20>;
			reg = <0x0 0x1100b000 0x0 0x1000>;
			vproc-supply = <0x8>;
		};

		syscfg_pctl_a@10005000 {
			compatible = "mediatek,mt8695-pctl-a-syscfg", "syscon";
			linux,phandle = <0xc>;
			phandle = <0xc>;
			reg = <0x0 0x10005000 0x0 0x1000>;
		};

		syscon@10000000 {
			#clock-cells = <0x1>;
			compatible = "mediatek,mt8695-topckgen", "syscon";
			linux,phandle = <0x3>;
			phandle = <0x3>;
			reg = <0x0 0x10000000 0x0 0x1000>;
		};

		syscon@10001000 {
			#clock-cells = <0x1>;
			compatible = "mediatek,mt8695-infracfg", "syscon";
			linux,phandle = <0xa>;
			phandle = <0xa>;
			reg = <0x0 0x10001000 0x0 0x1000>;
		};

		syscon@10003000 {
			#clock-cells = <0x1>;
			compatible = "mediatek,mt8695-pericfg", "syscon";
			linux,phandle = <0x18>;
			phandle = <0x18>;
			reg = <0x0 0x10003000 0x0 0x1000>;
		};

		syscon@10006000 {
			#power-domain-cells = <0x1>;
			clock-names = "mm", "axi_mfg", "venc", "demux", "eth_sel";
			clocks = <0x3 0x46 0x3 0x64 0x3 0x4a 0x3 0x7c 0x3 0x74>;
			compatible = "mediatek,mt8695-scpsys", "syscon";
			infracfg = <0xa>;
			linux,phandle = <0x17>;
			phandle = <0x17>;
			reg = <0x0 0x10006000 0x0 0x1000>;
		};

		syscon@10209000 {
			#clock-cells = <0x1>;
			compatible = "mediatek,mt8695-apmixedsys", "syscon";
			linux,phandle = <0x4>;
			phandle = <0x4>;
			reg = <0x0 0x10209000 0x0 0x1000>;
		};

		syscon@10220000 {
			#clock-cells = <0x1>;
			compatible = "mediatek,mt8695-mcucfg", "syscon";
			linux,phandle = <0x2>;
			phandle = <0x2>;
			reg = <0x0 0x10220000 0x0 0x1000>;
		};

		syscon@13ffe000 {
			#clock-cells = <0x1>;
			compatible = "mediatek,mt8695-mfgcfg", "syscon";
			linux,phandle = <0x41>;
			phandle = <0x41>;
			reg = <0x0 0x13ffe000 0x0 0x1000>;
		};

		syscon@14000000 {
			#clock-cells = <0x1>;
			compatible = "mediatek,mt8695-mmsys", "syscon";
			linux,phandle = <0x37>;
			phandle = <0x37>;
			reg = <0x0 0x14000000 0x0 0x1000>;
		};

		syscon@15000000 {
			#clock-cells = <0x1>;
			compatible = "mediatek,mt8695-disp", "syscon";
			linux,phandle = <0x38>;
			phandle = <0x38>;
			reg = <0x0 0x15000000 0x0 0x1000>;
		};

		syscon@1600f000 {
			#clock-cells = <0x1>;
			compatible = "mediatek,mt8695-vdecsoc", "syscon";
			linux,phandle = <0x3d>;
			phandle = <0x3d>;
			reg = <0x0 0x1600f000 0x0 0x1000>;
		};

		syscon@1602f000 {
			#clock-cells = <0x1>;
			compatible = "mediatek,mt8695-vdeccore", "syscon";
			linux,phandle = <0x3e>;
			phandle = <0x3e>;
			reg = <0x0 0x1602f000 0x0 0x1000>;
		};

		syscon@18000000 {
			#clock-cells = <0x1>;
			compatible = "mediatek,mt8695-vencsys", "syscon";
			linux,phandle = <0x3f>;
			phandle = <0x3f>;
			reg = <0x0 0x18000000 0x0 0x1000>;
		};

		syscon@19000000 {
			#clock-cells = <0x1>;
			compatible = "mediatek,mt8695-demuxsys", "syscon";
			linux,phandle = <0x42>;
			phandle = <0x42>;
			reg = <0x0 0x19000000 0x0 0x1000>;
		};

		systimer@1000c000 {
			clock-names = "clk13m";
			clocks = <0xb>;
			compatible = "mediatek,mt8695-systimer";
			interrupts = <0x0 0xb0 0x4 0x0 0xfc 0x4 0x0 0xfd 0x4 0x0 0xfe 0x4>;
			reg = <0x0 0x1000c000 0x0 0x60>;
		};

		systracker@10208000 {
			compatible = "mediatek,mt8695-bus_dbg";
			interrupts = <0x0 0x85 0x8>;
			reg = <0x0 0x10208000 0x0 0x1000>;
		};

		thermal-sensor {
			#thermal-sensor-cells = <0x0>;
			compatible = "generic-adc-thermal";
			io-channel-names = "sensor-channel";
			io-channels = <0x1e 0x0 0x1e 0x1 0x1e 0x2>;
		};

		thermal@1100b000 {
			#thermal-sensor-cells = <0x0>;
			apmixedsys = <0x4>;
			auxadc = <0x1e>;
			clock-names = "therm", "auxadc";
			clocks = <0x18 0x4 0x18 0x1b>;
			compatible = "mediatek,mt8695-thermal";
			interrupts = <0x0 0x6e 0x8>;
			linux,phandle = <0x4c>;
			nvmem-cell-names = "calibration-data";
			nvmem-cells = <0x1f>;
			pericfg = <0x18>;
			phandle = <0x4c>;
			reg = <0x0 0x1100b000 0x0 0x1000>;
		};

		toprgu@10007000 {
			#reset-cells = <0x1>;
			compatible = "mediatek,mt8695-wdt", "mediatek,mt6589-wdt";
			interrupts = <0x0 0x80 0x2>;
			reg = <0x0 0x10007000 0x0 0x1000>;
		};

		usb-phy@11500000 {
			#address-cells = <0x2>;
			#size-cells = <0x2>;
			compatible = "mediatek,mt2712-u3phy";
			ranges;
			status = "okay";

			usb-phy@11500000 {
				#phy-cells = <0x1>;
				clock-names = "ref";
				clocks = <0x21>;
				eye-patten-hstx-srctrl = <0xffffffff>;
				eye-patten-term-vref-sel = <0xffffffff>;
				eye-patten-vrt-vref-sel = <0xffffffff>;
				linux,phandle = <0x2f>;
				nvmem-cell-names = "internal-R-data";
				nvmem-cells = <0x35>;
				phandle = <0x2f>;
				reg = <0x0 0x11500000 0x0 0x400>;
				status = "okay";
			};

			usb-phy@11501000 {
				#phy-cells = <0x1>;
				clock-names = "ref";
				clocks = <0x21>;
				eye-patten-hstx-srctrl = <0x3>;
				eye-patten-term-vref-sel = <0x4>;
				eye-patten-vrt-vref-sel = <0x4>;
				linux,phandle = <0x2e>;
				nvmem-cell-names = "internal-R-data";
				nvmem-cells = <0x34>;
				phandle = <0x2e>;
				reg = <0x0 0x11501000 0x0 0x400>;
				status = "okay";
			};
		};

		usb@11271000 {
			#address-cells = <0x2>;
			#size-cells = <0x2>;
			clock-names = "sys_ck", "free_ck", "ahb_ck", "dma_ck";
			clocks = <0x3 0x50 0x21 0x18 0xe 0x18 0xe>;
			compatible = "mediatek,mt8695-mtu3";
			dr_mode = "otg";
			enable-manual-drd;
			extcon = <0x31>;
			interrupts = <0x0 0x7a 0x8>;
			phys = <0x2e 0x3 0x2f 0x3>;
			pinctrl-0 = <0x32>;
			pinctrl-1 = <0x32>;
			pinctrl-2 = <0x33>;
			pinctrl-names = "default", "id_float", "id_ground";
			power-domains = <0x17 0x8>;
			ranges;
			reg = <0x0 0x11271000 0x0 0x3000 0x0 0x11280700 0x0 0x100>;
			reg-names = "mac", "ippc";
			status = "okay";
			vbus-supply = <0x30>;

			xhci@11270000 {
				clock-names = "sys_ck", "free_ck", "ahb_ck", "dma_ck";
				clocks = <0x3 0x50 0x21 0x18 0xe 0x18 0xe>;
				compatible = "mediatek,mt8695-xhci";
				interrupts = <0x0 0x7b 0x8>;
				phys = <0x2e 0x3 0x2f 0x3>;
				power-domains = <0x17 0x8>;
				reg = <0x0 0x11270000 0x0 0x1000>;
				reg-names = "mac";
				status = "okay";
			};
		};

		vq@1500a000 {
			clock-names = "nr", "nr_sel", "univpll_d2", "vdo_di", "dispfmt_di", "wr_channel", "dramc_larb8", "di_sel", "tvdpll_d2", "osdpll_d3";
			clocks = <0x38 0xf 0x3 0x5e 0x3 0x19 0x38 0xd 0x38 0xe 0x38 0x10 0x38 0x6 0x3 0x7b 0x3 0x39 0x3 0x2e>;
			compatible = "mediatek,mt8695-vq";
			interrupts = <0x0 0x117 0x8 0x0 0x116 0x8 0x0 0x118 0x8 0x0 0x119 0x8 0x0 0x11a 0x8>;
			iommus = <0x16 0x100 0x16 0x101>;
			mediatek,larb = <0x15>;
			power-domains = <0x17 0x4>;
			reg = <0x0 0x1500a000 0x0 0x1000 0x0 0x15000000 0x0 0x100 0x0 0x1500e000 0x0 0x1000 0x0 0x1500f000 0x0 0x100 0x0 0x14000000 0x0 0x1000 0x0 0x14001500 0x0 0x100>;
		};
	};

	sound {
		compatible = "mediatek,mt8695-audio-card";
		mediatek,platform = <0x51>;
		status = "okay";
	};

	thermal-zones {

		board_thermal {
			policy = "trip_step_wise";
			polling-delay = <0x3e8>;
			polling-delay-passive = <0x64>;
			sustainable-power = <0x866>;
			thermal-sensors = <0x44>;

			cooling-maps {

				cpucore_cooling_map0 {
					contribution = <0x400>;
					cooling-device = <0x49 0x0 0x0>;
					trip = <0x45>;
				};

				cpucore_cooling_map1 {
					contribution = <0x400>;
					cooling-device = <0x49 0x0 0x0>;
					trip = <0x47>;
				};

				cpucore_cooling_map2 {
					contribution = <0x400>;
					cooling-device = <0x49 0x0 0x1>;
					trip = <0x48>;
				};

				cpufreq_cooling_map0 {
					contribution = <0x400>;
					cooling-device = <0x46 0x0 0x2>;
					trip = <0x45>;
				};

				cpufreq_cooling_map1 {
					contribution = <0x400>;
					cooling-device = <0x46 0x2 0x4>;
					trip = <0x47>;
				};

				cpufreq_cooling_map2 {
					contribution = <0x400>;
					cooling-device = <0x46 0x4 0x5>;
					trip = <0x48>;
				};

				gpufreq_cooling_map0 {
					contribution = <0x400>;
					cooling-device = <0x4a 0x0 0x0>;
					trip = <0x45>;
				};

				gpufreq_cooling_map1 {
					contribution = <0x400>;
					cooling-device = <0x4a 0x0 0x0>;
					trip = <0x47>;
				};

				gpufreq_cooling_map2 {
					contribution = <0x400>;
					cooling-device = <0x4a 0x0 0x1>;
					trip = <0x48>;
				};

				wifi_cooling_map0 {
					contribution = <0x400>;
					cooling-device = <0x4b 0x0 0x0>;
					trip = <0x45>;
				};

				wifi_cooling_map1 {
					contribution = <0x400>;
					cooling-device = <0x4b 0x0 0x0>;
					trip = <0x47>;
				};

				wifi_cooling_map2 {
					contribution = <0x400>;
					cooling-device = <0x4b 0x0 0x1>;
					trip = <0x48>;
				};
			};

			trips {

				trip-point@0 {
					hysteresis = <0x1f4>;
					linux,phandle = <0x45>;
					phandle = <0x45>;
					temperature = <0xdea8>;
					type = "passive";
				};

				trip-point@1 {
					hysteresis = <0x1f4>;
					linux,phandle = <0x47>;
					phandle = <0x47>;
					temperature = <0xe290>;
					type = "passive";
				};

				trip-point@2 {
					hysteresis = <0x1f4>;
					linux,phandle = <0x48>;
					phandle = <0x48>;
					temperature = <0xe678>;
					type = "passive";
				};

				trip-point@3 {
					hysteresis = <0x1f4>;
					temperature = <0xf618>;
					type = "critical";
				};
			};
		};

		soc_thermal {
			policy = "trip_step_wise";
			polling-delay = <0x3e8>;
			polling-delay-passive = <0x64>;
			sustainable-power = <0x866>;
			thermal-sensors = <0x4c>;

			cooling-maps {

				cpucore_cooling_map0 {
					contribution = <0x400>;
					cooling-device = <0x49 0x0 0x0>;
					trip = <0x4d>;
				};

				cpucore_cooling_map1 {
					contribution = <0x400>;
					cooling-device = <0x49 0x0 0x0>;
					trip = <0x4e>;
				};

				cpucore_cooling_map2 {
					contribution = <0x400>;
					cooling-device = <0x49 0x0 0x1>;
					trip = <0x4f>;
				};

				cpucore_cooling_map3 {
					contribution = <0x400>;
					cooling-device = <0x49 0x1 0x2>;
					trip = <0x50>;
				};

				cpufreq_cooling_map0 {
					contribution = <0x400>;
					cooling-device = <0x46 0x0 0x2>;
					trip = <0x4d>;
				};

				cpufreq_cooling_map1 {
					contribution = <0x400>;
					cooling-device = <0x46 0x2 0x4>;
					trip = <0x4e>;
				};

				cpufreq_cooling_map2 {
					contribution = <0x400>;
					cooling-device = <0x46 0x4 0x5>;
					trip = <0x4f>;
				};

				cpufreq_cooling_map3 {
					contribution = <0x400>;
					cooling-device = <0x46 0x5 0x6>;
					trip = <0x50>;
				};

				gpufreq_cooling_map0 {
					contribution = <0x400>;
					cooling-device = <0x4a 0x0 0x0>;
					trip = <0x4d>;
				};

				gpufreq_cooling_map1 {
					contribution = <0x400>;
					cooling-device = <0x4a 0x0 0x0>;
					trip = <0x4e>;
				};

				gpufreq_cooling_map2 {
					contribution = <0x400>;
					cooling-device = <0x4a 0x0 0x1>;
					trip = <0x4f>;
				};

				gpufreq_cooling_map3 {
					contribution = <0x400>;
					cooling-device = <0x4a 0x1 0x1>;
					trip = <0x50>;
				};

				wifi_cooling_map0 {
					contribution = <0x400>;
					cooling-device = <0x4b 0x0 0x0>;
					trip = <0x4d>;
				};

				wifi_cooling_map1 {
					contribution = <0x400>;
					cooling-device = <0x4b 0x0 0x1>;
					trip = <0x4e>;
				};

				wifi_cooling_map2 {
					contribution = <0x400>;
					cooling-device = <0x4b 0x1 0x2>;
					trip = <0x4f>;
				};

				wifi_cooling_map3 {
					contribution = <0x400>;
					cooling-device = <0x4b 0x2 0x2>;
					trip = <0x50>;
				};
			};

			trips {

				trip-point@0 {
					hysteresis = <0x3e8>;
					linux,phandle = <0x4d>;
					phandle = <0x4d>;
					temperature = <0x15f90>;
					type = "passive";
				};

				trip-point@1 {
					hysteresis = <0x3e8>;
					linux,phandle = <0x4e>;
					phandle = <0x4e>;
					temperature = <0x16f30>;
					type = "passive";
				};

				trip-point@2 {
					hysteresis = <0x3e8>;
					linux,phandle = <0x4f>;
					phandle = <0x4f>;
					temperature = <0x17ed0>;
					type = "passive";
				};

				trip-point@3 {
					hysteresis = <0x3e8>;
					linux,phandle = <0x50>;
					phandle = <0x50>;
					temperature = <0x18e70>;
					type = "passive";
				};

				trip-point@4 {
					hysteresis = <0x3e8>;
					temperature = <0x1adb0>;
					type = "critical";
				};
			};
		};
	};

	thermistor0 {
		adc_channel = <0x0>;
		compatible = "mtk,thermistor";
		device_name = "thermistor0";
		ntc_table = <0x7>;
		over_critical_low = <0x2fc44>;
		pull_up_resistor = <0x2710>;
		pull_up_voltage = <0x708>;
		status = "okay";
	};

	thermistor1 {
		adc_channel = <0x1>;
		compatible = "mtk,thermistor";
		device_name = "thermistor1";
		ntc_table = <0x7>;
		over_critical_low = <0x2fc44>;
		pull_up_resistor = <0x2710>;
		pull_up_voltage = <0x708>;
		status = "okay";
	};

	timer {
		compatible = "arm,armv8-timer";
		interrupt-parent = <0x9>;
		interrupts = <0x1 0xd 0xf08 0x1 0xe 0xf08 0x1 0xb 0xf08 0x1 0xa 0xf08>;
	};

	virtual-sensor {
		#thermal-sensor-cells = <0x0>;
		compatible = "amazon,virtual_sensor";
		linux,phandle = <0x44>;
		phandle = <0x44>;

		cooling_devices {
		};

		vs_components {

			vs_thermistor0 {
				alpha = <0x6>;
				offset = <0xfffffd3a>;
				vs_name = "thermistor0";
				weight = <0x31d>;
			};

			vs_thermistor1 {
				alpha = <0x2d0>;
				offset = <0xd610>;
				vs_name = "thermistor1";
				weight = <0x0>;
			};
		};
	};

	wifi {
		compatible = "mediatek,mt7668_wifi_ctrl";
		interrupt-parent = <0x2b>;
		interrupts = <0x21 0x2>;
		pinctrl-0 = <0x43>;
		pinctrl-names = "default";
		status = "okay";
	};
};
